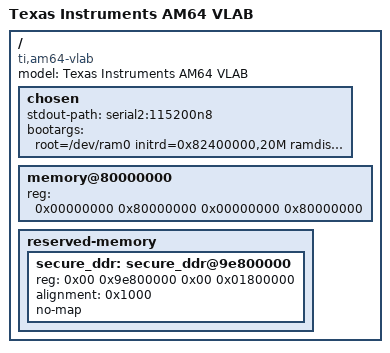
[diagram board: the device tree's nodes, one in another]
// SPDX-License-Identifier: GPL-2.0
/*
 * Copyright (C) 2019 Texas Instruments Incorporated - http://www.ti.com/
 */

/dts-v1/;

#include "k3-am64x.dtsi"

/ {
	compatible =  "ti,am64-vlab", "ti,am64";
	model = "Texas Instruments AM64 VLAB";

	chosen {
		stdout-path = "serial2:115200n8";
		bootargs = "root=/dev/ram0 initrd=0x82400000,20M ramdisk_size=20480 init=/bin/sh console=ttyS2,115200n8 earlycon=ns16550a,mmio32,0x02800000";
	};

	memory@80000000 {
		device_type = "memory";
		/* 2G RAM */
		reg = <0x00000000 0x80000000 0x00000000 0x80000000>;

	};

	reserved-memory {
		#address-cells = <2>;
		#size-cells = <2>;
		ranges;
		secure_ddr: secure_ddr@9e800000 {
			reg = <0x00 0x9e800000 0x00 0x01800000>; /* for OP-TEE */
			alignment = <0x1000>;
			no-map;
		};
	};
};
